# NM1330AE_v1 register map
File version: 1.0
Registers are 32-bit, read-write, reset 0x0 unless marked. A register's access mark holds for its fields unless they carry their own. Offsets are from the block's base; [hi:lo] are bit positions; 'fields as' and 'values as' point back to an identical list.

## ACMP01 — ACMP Register Map
Base 0x400D0000
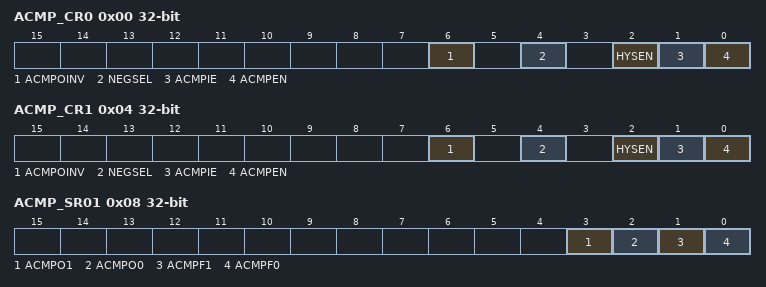
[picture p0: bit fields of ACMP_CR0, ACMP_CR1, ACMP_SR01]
0x00 ACMP_CR0 — Analog Comparator 0 Control Register
  [6] ACMPOINV — Analog Comparator 0 Output Inverse Enable Control
    0=The comparator output inverse function Disabled; 1=The comparator output inverse function Enabled
  [4] NEGSEL — Analog Comparator 0 Negative Input Selection
    0=The source of the negative comparator input is from ACMP0_N pin; 1=The internal band-gap voltage is selected as the source of negative comparator input
  [2] HYSEN — Analog Comparator 0 Hysteresis Enable Control
    0=Hysteresis function Disabled; 1=Hysteresis function Enabled
  [1] ACMPIE — Analog Comparator 0 Interrupt Enable Control
    0=Interrupt function Disabled; 1=Interrupt function Enabled
  [0] ACMPEN — Analog Comparator 0 Enable Control. Note: Analog comparator output needs to wait 2 us stable time after ACMPEN is set.
    0=Analog Comparator 0 Disabled; 1=Analog Comparator 0 Enabled
0x04 ACMP_CR1 — Analog Comparator 1 Control Register
  [6] ACMPOINV — Analog Comparator 1 Output Inverse Enable Control
    values as ACMP_CR0.ACMPOINV
  [4] NEGSEL — Analog Comparator 1 Negative Input Selection
    0=The source of the negative comparator input is from ACMP1_N pin; 1=The internal band-gap voltage is selected as the source of negative comparator input
  [2] HYSEN — Analog Comparator 1 Hysteresis Enable Control
    values as ACMP_CR0.HYSEN
  [1] ACMPIE — Analog Comparator 1 Interrupt Enable Control
    0=Interrupt function Disabled; 1=Interrupt function Enabled
  [0] ACMPEN — Analog Comparator 1 Enable Control. Note: Analog comparator output needs to wait 2 us stable time after ACMPEN is set.
    0=Analog comparator 1 Disabled; 1=Analog comparator 1 Enabled
0x08 ACMP_SR01 — Analog Comparator 0/1 Status Register
  [3] ACMPO1 — Analog Comparator 1 Output
    0=Analog comparator 1 outputs 0; 1=Analog comparator 1 outputs 1
  [2] ACMPO0 — Analog Comparator 0 Output
    0=Analog comparator 0 outputs 0; 1=Analog comparator 0 outputs 1
  [1] ACMPF1 — Analog Comparator 1 Flag. This bit is set by hardware whenever the comparator 1 output changes state. This will generate an interrupt if ACMP_CR1[1] is set to 1. Note: Write 1 to clear this bit to 0.
    0=Analog comparator 1 output does not change; 1=Analog comparator 1 output changed since this bit was cleared to 0
  [0] ACMPF0 — Analog Comparator 0 Flag. This bit is set by hardware whenever the comparator 0 output changes state. This will generate an interrupt if ACMP_CR0[1] is set to 1. Note: Write 1 to clear this bit to 0.
    0=Analog comparator 0 output does not change; 1=Analog comparator 0 output changed since this bit was cleared to 0

## ACMP23 — ACMP Register Map
Base 0x401D0000
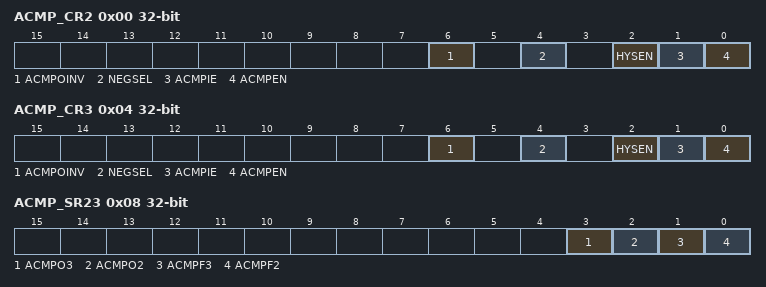
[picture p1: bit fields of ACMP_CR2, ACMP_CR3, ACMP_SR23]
0x00 ACMP_CR2 — Analog Comparator 2 Control Register
  [6] ACMPOINV — Analog Comparator 2 Output Inverse Enable Control
    0=The comparator output inverse function Disabled; 1=The comparator output inverse function Enabled
  [4] NEGSEL — Analog Comparator 2 Negative Input Selection
    0=The source of the negative comparator input is from ACMP2_N pin; 1=The internal band-gap voltage is selected as the source of negative comparator input
  [2] HYSEN — Analog Comparator 2 Hysteresis Enable Control
    0=Hysteresis function Disabled; 1=Hysteresis function Enabled
  [1] ACMPIE — Analog Comparator 2 Interrupt Enable Control
    0=Interrupt function Disabled; 1=Interrupt function Enabled
  [0] ACMPEN — Analog Comparator 2 Enable Control. Note: Analog comparator output needs to wait 2 us stable time after ACMPEN is set.
    0=Analog Comparator 2 Disabled; 1=Analog Comparator 2 Enabled
0x04 ACMP_CR3 — Analog Comparator 3 Control Register
  [6] ACMPOINV — Analog Comparator 3 Output Inverse Enable Control
    values as ACMP_CR2.ACMPOINV
  [4] NEGSEL — Analog Comparator 3 Negative Input Selection
    0=The source of the negative comparator input is from ACMP3_N pin; 1=The internal band-gap voltage is selected as the source of negative comparator input
  [2] HYSEN — Analog Comparator 3 Hysteresis Enable Control
    values as ACMP_CR2.HYSEN
  [1] ACMPIE — Analog Comparator 3 Interrupt Enable Control
    0=Interrupt function Disabled; 1=Interrupt function Enabled
  [0] ACMPEN — Analog Comparator 3 Enable Control. Note: Analog comparator output needs to wait 2 us stable time after ACMPEN is set.
    0=Analog comparator 3 Disabled; 1=Analog comparator 3 Enabled
0x08 ACMP_SR23 — Analog Comparator 2/3 Status Register
  [3] ACMPO3 — Analog Comparator 3 Output
    0=Analog comparator 3 outputs 0; 1=Analog comparator 3 outputs 1
  [2] ACMPO2 — Analog Comparator 2 Output
    0=Analog comparator 2 outputs 0; 1=Analog comparator 2 outputs 1
  [1] ACMPF3 — Analog Comparator 3 Flag. This bit is set by hardware whenever the comparator 3 output changes state. This will generate an interrupt if ACMP_CR3[1] is set to 1. Note: Write 1 to clear this bit to 0.
    0=Analog comparator 3 output does not change; 1=Analog comparator 3 output changed since this bit was cleared to 0
  [0] ACMPF2 — Analog Comparator 2 Flag. This bit is set by hardware whenever the comparator 2 output changes state. This will generate an interrupt if ACMP_CR2[1] is set to 1. Note: Write 1 to clear this bit to 0.
    0=Analog comparator 2 output does not change; 1=Analog comparator 2 output changed since this bit was cleared to 0
